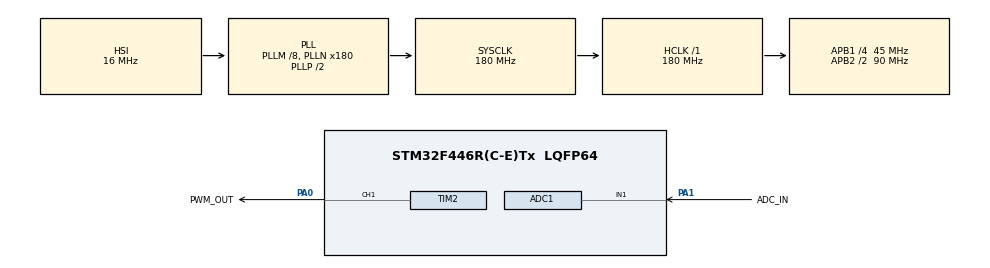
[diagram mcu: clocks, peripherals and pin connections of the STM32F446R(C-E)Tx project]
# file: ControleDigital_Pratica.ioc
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ADC1.Channel-0\#ChannelRegularConversion=ADC_CHANNEL_1
ADC1.ClockPrescaler=ADC_CLOCK_SYNC_PCLK_DIV4
ADC1.ExternalTrigConv=ADC_EXTERNALTRIGCONV_T2_TRGO
ADC1.NbrOfConversionFlag=1
ADC1.Rank-0\#ChannelRegularConversion=1
ADC1.SamplingTime-0\#ChannelRegularConversion=ADC_SAMPLETIME_15CYCLES
ADC1.master=1
Mcu.Family=STM32F4
Mcu.Name=STM32F446R(C-E)Tx
Mcu.Package=LQFP64
NVIC.ADC_IRQn=true\:0\:0\:false\:false\:true\:true\:true\:true
NVIC.PriorityGroup=NVIC_PRIORITYGROUP_4
NVIC.TIM2_IRQn=true\:0\:0\:false\:false\:true\:true\:true\:true
PA0-WKUP.GPIO_Label=PWM_OUT
PA0-WKUP.Signal=S_TIM2_CH1_ETR
PA1.GPIO_Label=ADC_IN
PA1.Signal=ADCx_IN1
ProjectManager.HeapSize=0x200
ProjectManager.StackSize=0x400
ProjectManager.TargetToolchain=STM32CubeIDE
RCC.AHBFreq_Value=180000000
RCC.APB1CLKDivider=RCC_HCLK_DIV4
RCC.APB1Freq_Value=45000000
RCC.APB1TimFreq_Value=90000000
RCC.APB2CLKDivider=RCC_HCLK_DIV2
RCC.APB2Freq_Value=90000000
RCC.APB2TimFreq_Value=180000000
RCC.CortexFreq_Value=180000000
RCC.HCLKFreq_Value=180000000
RCC.PLLM=8
RCC.PLLN=180
RCC.SYSCLKFreq_VALUE=180000000
RCC.SYSCLKSource=RCC_SYSCLKSOURCE_PLLCLK
RCC.USBFreq_Value=180000000
RCC.VCOOutputFreq_Value=360000000
SH.ADCx_IN1.0=ADC1_IN1,IN1
SH.S_TIM2_CH1_ETR.0=TIM2_CH1,PWM Generation1 CH1
TIM2.AutoReloadPreload=TIM_AUTORELOAD_PRELOAD_ENABLE
TIM2.Channel-PWM\ Generation1\ CH1=TIM_CHANNEL_1
TIM2.Period=4499
TIM2.Prescaler=0
TIM2.TIM_MasterOutputTrigger=TIM_TRGO_UPDATE
VP_TIM2_VS_ClockSourceINT.Mode=Internal
board=custom

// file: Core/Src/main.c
/* USER CODE BEGIN Header */
/**
  ******************************************************************************
  * @file           : main.c
  * @brief          : Main program body
  ******************************************************************************
  * @attention
  *
  * Copyright (c) 2026 STMicroelectronics.
  * All rights reserved.
  *
  * This software is licensed under terms that can be found in the LICENSE file
  * in the root directory of this software component.
  * If no LICENSE file comes with this software, it is provided AS-IS.
  *
  ******************************************************************************
  */
/* USER CODE END Header */
#include "main.h"

/* USER CODE BEGIN Includes */
#include "math.h"
/* USER CODE END Includes */

/* USER CODE BEGIN PD */
#define PWM_STEPS    4500u        /* ARR + 1 */
#define SINE_LEN     1024u
#define F_PWM        20000.0f
#define F_SIGNAL     60.0f
/* USER CODE END PD */

ADC_HandleTypeDef hadc1;

TIM_HandleTypeDef htim2;

/* USER CODE BEGIN PV */
typedef enum { WAVE_SINE, WAVE_TRAP, WAVE_TRIA } wave_t;
volatile wave_t wave = WAVE_SINE;

static uint16_t sine_tab[SINE_LEN];
static uint32_t phase = 0;
static uint32_t phase_step;
static uint32_t sd_acc = 0;
/* USER CODE END PV */

void SystemClock_Config(void);
static void MX_GPIO_Init(void);
static void MX_ADC1_Init(void);
static void MX_TIM2_Init(void);

/* USER CODE BEGIN 0 */

static inline void pwm_set_duty16(uint16_t duty16)
{
    sd_acc += (uint32_t)duty16 * PWM_STEPS;
    uint32_t ccr = sd_acc >> 16;
    sd_acc &= 0xFFFF;
    __HAL_TIM_SET_COMPARE(&htim2, TIM_CHANNEL_1, ccr);
}

static uint16_t trapezoid16(uint16_t p)        /* p: fase 0..65535 */
{
    if (p < 16384)  return (uint16_t)(p * 4u);               /* sobe   */
    if (p < 32768)  return 65535;                            /* alto   */
    if (p < 49152)  return (uint16_t)((49152u - p) * 4u);    /* desce  */
    return 0;                                                /* baixo  */
}

static uint16_t triangle16(uint16_t p)        /* p: fase 0..65535 */
{
    if (p < 32768)
        return (uint16_t)(p * 2u);            /* sobe: 0 -> 65534 */
    else
        return (uint16_t)((65535u - p) * 2u); /* desce: 65534 -> 0 */
}
/* USER CODE END 0 */

int main(void)
{

  /* MCU Configuration--------------------------------------------------------*/

  /* Reset of all peripherals, Initializes the Flash interface and the Systick. */
  HAL_Init();

  /* Configure the system clock */
  SystemClock_Config();

  /* Initialize all configured peripherals */
  MX_GPIO_Init();
  MX_ADC1_Init();
  MX_TIM2_Init();
  /* USER CODE BEGIN 2 */

  for (uint32_t i = 0; i < SINE_LEN; i++)
  {
      float s = sinf(2.0f * 3.14159265f * i / SINE_LEN);   /* -1..+1 */
      sine_tab[i] = (uint16_t)(32767.5f + 32767.0f * s);   /* 0..65535 */
  }
  phase_step = (uint32_t)(F_SIGNAL * 4294967296.0f / F_PWM);

  HAL_TIM_Base_Start_IT(&htim2);                 /* interrupção de update, 20 kHz */
  HAL_TIM_PWM_Start(&htim2, TIM_CHANNEL_1);      /* saída PWM em PA0 */

  /* USER CODE END 2 */

  /* Infinite loop */
  while (1)
  {

  }
}

void SystemClock_Config(void)
{
  RCC_OscInitTypeDef RCC_OscInitStruct = {0};
  RCC_ClkInitTypeDef RCC_ClkInitStruct = {0};

  /** Configure the main internal regulator output voltage
  */
  __HAL_RCC_PWR_CLK_ENABLE();
  __HAL_PWR_VOLTAGESCALING_CONFIG(PWR_REGULATOR_VOLTAGE_SCALE1);

  /** Initializes the RCC Oscillators according to the specified parameters
  * in the RCC_OscInitTypeDef structure.
  */
  RCC_OscInitStruct.OscillatorType = RCC_OSCILLATORTYPE_HSI;
  RCC_OscInitStruct.HSIState = RCC_HSI_ON;
  RCC_OscInitStruct.HSICalibrationValue = RCC_HSICALIBRATION_DEFAULT;
  RCC_OscInitStruct.PLL.PLLState = RCC_PLL_ON;
  RCC_OscInitStruct.PLL.PLLSource = RCC_PLLSOURCE_HSI;
  RCC_OscInitStruct.PLL.PLLM = 8;
  RCC_OscInitStruct.PLL.PLLN = 180;
  RCC_OscInitStruct.PLL.PLLP = RCC_PLLP_DIV2;
  RCC_OscInitStruct.PLL.PLLQ = 2;
  RCC_OscInitStruct.PLL.PLLR = 2;
  if (HAL_RCC_OscConfig(&RCC_OscInitStruct) != HAL_OK)
  {
    Error_Handler();
  }

  /** Activate the Over-Drive mode
  */
  if (HAL_PWREx_EnableOverDrive() != HAL_OK)
  {
    Error_Handler();
  }

  /** Initializes the CPU, AHB and APB buses clocks
  */
  RCC_ClkInitStruct.ClockType = RCC_CLOCKTYPE_HCLK|RCC_CLOCKTYPE_SYSCLK
                              |RCC_CLOCKTYPE_PCLK1|RCC_CLOCKTYPE_PCLK2;
  RCC_ClkInitStruct.SYSCLKSource = RCC_SYSCLKSOURCE_PLLCLK;
  RCC_ClkInitStruct.AHBCLKDivider = RCC_SYSCLK_DIV1;
  RCC_ClkInitStruct.APB1CLKDivider = RCC_HCLK_DIV4;
  RCC_ClkInitStruct.APB2CLKDivider = RCC_HCLK_DIV2;

  if (HAL_RCC_ClockConfig(&RCC_ClkInitStruct, FLASH_LATENCY_5) != HAL_OK)
  {
    Error_Handler();
  }
}

static void MX_ADC1_Init(void)
{

  ADC_ChannelConfTypeDef sConfig = {0};

  /** Configure the global features of the ADC (Clock, Resolution, Data Alignment and number of conversion)
  */
  hadc1.Instance = ADC1;
  hadc1.Init.ClockPrescaler = ADC_CLOCK_SYNC_PCLK_DIV4;
  hadc1.Init.Resolution = ADC_RESOLUTION_12B;
  hadc1.Init.ScanConvMode = DISABLE;
  hadc1.Init.ContinuousConvMode = DISABLE;
  hadc1.Init.DiscontinuousConvMode = DISABLE;
  hadc1.Init.ExternalTrigConvEdge = ADC_EXTERNALTRIGCONVEDGE_RISING;
  hadc1.Init.ExternalTrigConv = ADC_EXTERNALTRIGCONV_T2_TRGO;
  hadc1.Init.DataAlign = ADC_DATAALIGN_RIGHT;
  hadc1.Init.NbrOfConversion = 1;
  hadc1.Init.DMAContinuousRequests = DISABLE;
  hadc1.Init.EOCSelection = ADC_EOC_SINGLE_CONV;
  if (HAL_ADC_Init(&hadc1) != HAL_OK)
  {
    Error_Handler();
  }

  /** Configure for the selected ADC regular channel its corresponding rank in the sequencer and its sample time.
  */
  sConfig.Channel = ADC_CHANNEL_1;
  sConfig.Rank = 1;
  sConfig.SamplingTime = ADC_SAMPLETIME_15CYCLES;
  if (HAL_ADC_ConfigChannel(&hadc1, &sConfig) != HAL_OK)
  {
    Error_Handler();
  }

}

static void MX_TIM2_Init(void)
{

  TIM_ClockConfigTypeDef sClockSourceConfig = {0};
  TIM_MasterConfigTypeDef sMasterConfig = {0};
  TIM_OC_InitTypeDef sConfigOC = {0};

  htim2.Instance = TIM2;
  htim2.Init.Prescaler = 0;
  htim2.Init.CounterMode = TIM_COUNTERMODE_UP;
  htim2.Init.Period = 4499;
  htim2.Init.ClockDivision = TIM_CLOCKDIVISION_DIV1;
  htim2.Init.AutoReloadPreload = TIM_AUTORELOAD_PRELOAD_ENABLE;
  if (HAL_TIM_Base_Init(&htim2) != HAL_OK)
  {
    Error_Handler();
  }
  sClockSourceConfig.ClockSource = TIM_CLOCKSOURCE_INTERNAL;
  if (HAL_TIM_ConfigClockSource(&htim2, &sClockSourceConfig) != HAL_OK)
  {
    Error_Handler();
  }
  if (HAL_TIM_PWM_Init(&htim2) != HAL_OK)
  {
    Error_Handler();
  }
  sMasterConfig.MasterOutputTrigger = TIM_TRGO_UPDATE;
  sMasterConfig.MasterSlaveMode = TIM_MASTERSLAVEMODE_DISABLE;
  if (HAL_TIMEx_MasterConfigSynchronization(&htim2, &sMasterConfig) != HAL_OK)
  {
    Error_Handler();
  }
  sConfigOC.OCMode = TIM_OCMODE_PWM1;
  sConfigOC.Pulse = 0;
  sConfigOC.OCPolarity = TIM_OCPOLARITY_HIGH;
  sConfigOC.OCFastMode = TIM_OCFAST_DISABLE;
  if (HAL_TIM_PWM_ConfigChannel(&htim2, &sConfigOC, TIM_CHANNEL_1) != HAL_OK)
  {
    Error_Handler();
  }
  HAL_TIM_MspPostInit(&htim2);

}

static void MX_GPIO_Init(void)
{

  /* GPIO Ports Clock Enable */
  __HAL_RCC_GPIOA_CLK_ENABLE();

}

/* USER CODE BEGIN 4 */

void HAL_TIM_PeriodElapsedCallback(TIM_HandleTypeDef *htim)
{
    if (htim->Instance == TIM2)
    {
        phase += phase_step;
        uint16_t duty16;

        switch (wave)
        {
            case WAVE_SINE: duty16 = sine_tab[phase >> 22];    break;
            case WAVE_TRAP: duty16 = trapezoid16(phase >> 16); break;
            case WAVE_TRIA:  duty16 = triangle16(phase >> 16); break;
            default:        duty16 = 0;                        break;
        }

        pwm_set_duty16(duty16);
    }
}

/* USER CODE END 4 */

void Error_Handler(void)
{
  __disable_irq();
  while (1)
  {
  }
}
